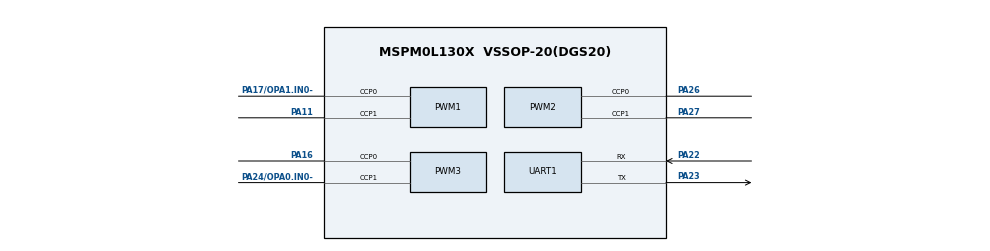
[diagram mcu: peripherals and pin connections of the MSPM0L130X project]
/**
 * @cliArgs --device "MSPM0L130X" --part "Default" --package "VSSOP-20(DGS20)" --product "mspm0_sdk@2.10.00.04"
 * @versions {"tool":"1.26.2+4477"}
 */

/**
 * Import the modules used in this configuration.
 */
const GPIO    = scripting.addModule("/ti/driverlib/GPIO", {}, false);
const GPIO1   = GPIO.addInstance();
const PWM     = scripting.addModule("/ti/driverlib/PWM", {}, false);
const PWM1    = PWM.addInstance();
const PWM2    = PWM.addInstance();
const PWM3    = PWM.addInstance();
const SYSCTL  = scripting.addModule("/ti/driverlib/SYSCTL");
const SYSTICK = scripting.addModule("/ti/driverlib/SYSTICK");
const UART    = scripting.addModule("/ti/driverlib/UART", {}, false);
const UART1   = UART.addInstance();

/**
 * Write custom configuration values to the imported modules.
 */
GPIO1.$name                         = "LED";
GPIO1.port                          = "PORTA";
GPIO1.associatedPins.create(2);
GPIO1.associatedPins[0].assignedPin = "4";
GPIO1.associatedPins[0].$name       = "Red";
GPIO1.associatedPins[1].$name       = "Green";
GPIO1.associatedPins[1].assignedPin = "6";

const Board = scripting.addModule("/ti/driverlib/Board", {}, false);

PWM1.pwmMode                            = "EDGE_ALIGN_UP";
PWM1.clockPrescale                      = 32;
PWM1.timerCount                         = 10000;
PWM1.$name                              = "PWM_U7_WEAPON";
PWM1.peripheral.$assign                 = "TIMG4";
PWM1.peripheral.ccp0Pin.$assign         = "PA17/OPA1.IN0-";
PWM1.peripheral.ccp1Pin.$assign         = "PA11";
PWM1.PWM_CHANNEL_0.$name                = "ti_driverlib_pwm_PWMTimerCC0";
PWM1.PWM_CHANNEL_1.$name                = "ti_driverlib_pwm_PWMTimerCC1";
PWM1.ccp0PinConfig.direction            = scripting.forceWrite("OUTPUT");
PWM1.ccp0PinConfig.hideOutputInversion  = scripting.forceWrite(false);
PWM1.ccp0PinConfig.onlyInternalResistor = scripting.forceWrite(false);
PWM1.ccp0PinConfig.passedPeripheralType = scripting.forceWrite("Digital");
PWM1.ccp0PinConfig.$name                = "ti_driverlib_gpio_GPIOPinGeneric2";
PWM1.ccp1PinConfig.direction            = scripting.forceWrite("OUTPUT");
PWM1.ccp1PinConfig.hideOutputInversion  = scripting.forceWrite(false);
PWM1.ccp1PinConfig.onlyInternalResistor = scripting.forceWrite(false);
PWM1.ccp1PinConfig.passedPeripheralType = scripting.forceWrite("Digital");
PWM1.ccp1PinConfig.$name                = "ti_driverlib_gpio_GPIOPinGeneric3";

PWM2.pwmMode                            = "EDGE_ALIGN_UP";
PWM2.timerCount                         = 10000;
PWM2.clockPrescale                      = 32;
PWM2.$name                              = "PWM_U5_LEFT";
PWM2.peripheral.$assign                 = "TIMG1";
PWM2.peripheral.ccp0Pin.$assign         = "PA26";
PWM2.peripheral.ccp1Pin.$assign         = "PA27";
PWM2.PWM_CHANNEL_0.$name                = "ti_driverlib_pwm_PWMTimerCC2";
PWM2.PWM_CHANNEL_1.$name                = "ti_driverlib_pwm_PWMTimerCC3";
PWM2.ccp0PinConfig.direction            = scripting.forceWrite("OUTPUT");
PWM2.ccp0PinConfig.hideOutputInversion  = scripting.forceWrite(false);
PWM2.ccp0PinConfig.onlyInternalResistor = scripting.forceWrite(false);
PWM2.ccp0PinConfig.passedPeripheralType = scripting.forceWrite("Digital");
PWM2.ccp0PinConfig.$name                = "ti_driverlib_gpio_GPIOPinGeneric4";
PWM2.ccp1PinConfig.direction            = scripting.forceWrite("OUTPUT");
PWM2.ccp1PinConfig.hideOutputInversion  = scripting.forceWrite(false);
PWM2.ccp1PinConfig.onlyInternalResistor = scripting.forceWrite(false);
PWM2.ccp1PinConfig.passedPeripheralType = scripting.forceWrite("Digital");
PWM2.ccp1PinConfig.$name                = "ti_driverlib_gpio_GPIOPinGeneric5";

PWM3.$name                              = "PWM_U6_RIGHT";
PWM3.clockPrescale                      = 32;
PWM3.timerCount                         = 10000;
PWM3.pwmMode                            = "EDGE_ALIGN_UP";
PWM3.peripheral.$assign                 = "TIMG0";
PWM3.peripheral.ccp0Pin.$assign         = "PA16";
PWM3.peripheral.ccp1Pin.$assign         = "PA24/OPA0.IN0-";
PWM3.PWM_CHANNEL_0.$name                = "ti_driverlib_pwm_PWMTimerCC4";
PWM3.PWM_CHANNEL_1.$name                = "ti_driverlib_pwm_PWMTimerCC5";
PWM3.ccp0PinConfig.direction            = scripting.forceWrite("OUTPUT");
PWM3.ccp0PinConfig.hideOutputInversion  = scripting.forceWrite(false);
PWM3.ccp0PinConfig.onlyInternalResistor = scripting.forceWrite(false);
PWM3.ccp0PinConfig.passedPeripheralType = scripting.forceWrite("Digital");
PWM3.ccp0PinConfig.$name                = "ti_driverlib_gpio_GPIOPinGeneric0";
PWM3.ccp1PinConfig.direction            = scripting.forceWrite("OUTPUT");
PWM3.ccp1PinConfig.hideOutputInversion  = scripting.forceWrite(false);
PWM3.ccp1PinConfig.onlyInternalResistor = scripting.forceWrite(false);
PWM3.ccp1PinConfig.passedPeripheralType = scripting.forceWrite("Digital");
PWM3.ccp1PinConfig.$name                = "ti_driverlib_gpio_GPIOPinGeneric1";

SYSCTL.BORThresh = "2";

SYSTICK.interruptEnable = true;
SYSTICK.systickEnable   = true;
SYSTICK.periodEnable    = true;
SYSTICK.period          = 160000;

UART1.$name                    = "UART_0";
UART1.targetBaudRate           = 420000;
UART1.interruptPriority        = "1";
UART1.enabledInterrupts        = ["BREAK_ERROR","FRAMING_ERROR","OVERRUN_ERROR","PARITY_ERROR","RX"];
UART1.peripheral.$assign       = "UART0";
UART1.peripheral.rxPin.$assign = "PA22";
UART1.peripheral.txPin.$assign = "PA23";
UART1.txPinConfig.$name        = "ti_driverlib_gpio_GPIOPinGeneric6";
UART1.rxPinConfig.$name        = "ti_driverlib_gpio_GPIOPinGeneric7";

const ProjectConfig              = scripting.addModule("/ti/project_config/ProjectConfig", {}, false);
ProjectConfig.migrationCondition = true;

/**
 * Pinmux solution for unlocked pins/peripherals. This ensures that minor changes to the automatic solver in a future
 * version of the tool will not impact the pinmux you originally saw.  These lines can be completely deleted in order to
 * re-solve from scratch.
 */
GPIO1.associatedPins[0].pin.$suggestSolution = "PA4";
GPIO1.associatedPins[1].pin.$suggestSolution = "PA6";
Board.peripheral.$suggestSolution            = "DEBUGSS";
Board.peripheral.swclkPin.$suggestSolution   = "PA20";
Board.peripheral.swdioPin.$suggestSolution   = "PA19";
SYSCTL.peripheral.$suggestSolution           = "SYSCTL";
